# STM32C5A3xx register map
File version: 1.0
Registers are 32-bit, read-write, reset 0x0 unless marked. A register's access mark holds for its fields unless they carry their own. Offsets are from the block's base; [hi:lo] are bit positions; {n}, {i} and the like mark numbered series.

## ICACHE — Instruction cache (ICACHE)
Base 0x40030400
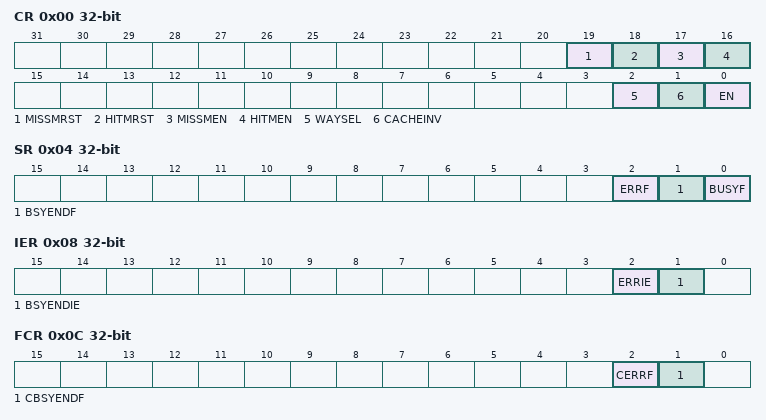
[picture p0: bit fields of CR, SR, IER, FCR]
0x00 CR — ICACHE control register
  [19] MISSMRST — miss monitor reset
  [18] HITMRST — hit monitor reset
  [17] MISSMEN — miss monitor enable
  [16] HITMEN — hit monitor enable
  [2] WAYSEL — cache associativity mode selection
  [1] CACHEINV — cache invalidation
  [0] EN — enable
0x04 SR ro — ICACHE status register
  [2] ERRF — cache error flag
  [1] BSYENDF — busy end flag
  [0] BUSYF — busy flag
0x08 IER — ICACHE interrupt enable register
  [2] ERRIE — interrupt enable on cache error
  [1] BSYENDIE — interrupt enable on busy end
0x0C FCR — ICACHE flag clear register
  [2] CERRF — clear cache error flag
  [1] CBSYENDF — clear busy end flag
0x10 HMONR ro — ICACHE hit monitor register
  [31:0] HITMON — cache hit monitor counter
0x14 MMONR ro — ICACHE miss monitor register
  [15:0] MISSMON — cache miss monitor counter
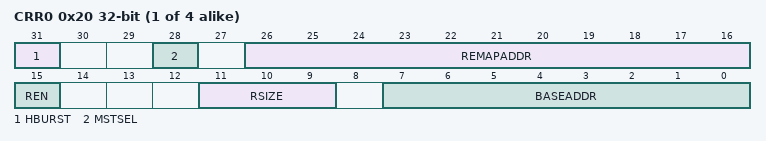
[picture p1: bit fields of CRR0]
{0x20+4i} CRR{i} (i=0..3) — ICACHE region {i} configuration register
  [31] HBURST — output burst type for region x
  [28] MSTSEL — AHB cache master selection for region x
  [26:16] REMAPADDR — remapped address for region x
  [15] REN — enable for region x
  [11:9] RSIZE — size for region x
  [7:0] BASEADDR — base address for region x

## GPIOA — General Purpose I/O (GPIO)
Base 0x42020000
Same registers: GPIOB 0x42020400, GPIOC 0x42020800, GPIOD 0x42020C00, GPIOE 0x42021000, GPIOF 0x42021400, GPIOG 0x42021800, GPIOH 0x42021C00
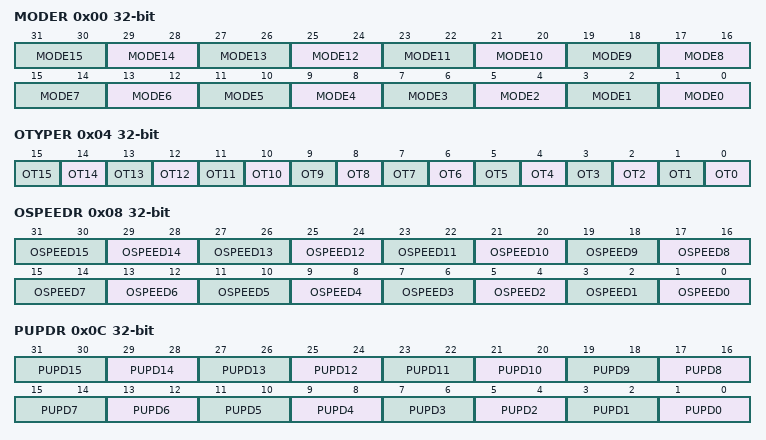
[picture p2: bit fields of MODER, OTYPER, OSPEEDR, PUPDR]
0x00 MODER — GPIO port mode register
  [2n+1:2n] MODE{n} (n=0..15) — Port x configuration I/O pin y
0x04 OTYPER — GPIO port output type register
  [n] OT{n} (n=0..15) — Port x configuration I/O pin y
0x08 OSPEEDR — GPIO port output speed register
  [2n+1:2n] OSPEED{n} (n=0..15) — Port x configuration I/O pin y
0x0C PUPDR — GPIO port pull-up/pull-down register
  [2n+1:2n] PUPD{n} (n=0..15) — Port x configuration I/O pin y
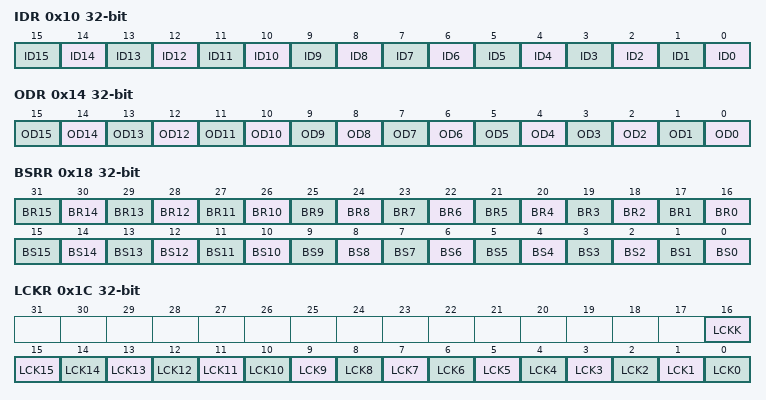
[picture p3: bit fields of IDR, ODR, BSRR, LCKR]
0x10 IDR ro — GPIO port input data register
  [n] ID{n} (n=0..15) — Port x input data I/O pin y
0x14 ODR — GPIO port output data register
  [n] OD{n} (n=0..15) — Port output data I/O pin y
0x18 BSRR — GPIO port bit set/reset register
  [n+16] BR{n} (n=0..15) — Port x reset I/O pin y
  [n] BS{n} (n=0..15) — Port x set I/O pin y
0x1C LCKR — GPIO port configuration lock register
  [16] LCKK — Lock key
  [n] LCK{n} (n=0..15) — Port x lock I/O pin y
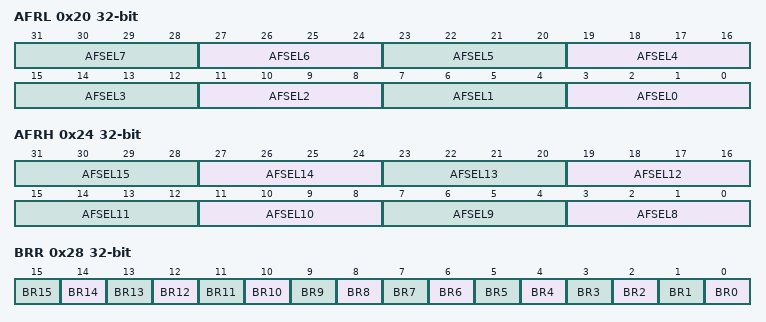
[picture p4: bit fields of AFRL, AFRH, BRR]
0x20 AFRL — GPIO alternate function register
  [4n+3:4n] AFSEL{n} (n=0..7)
0x24 AFRH — GPIO alternate function register
  [4n-29:4n-32] AFSEL{n} (n=8..15)
0x28 BRR — GPIO port bit reset register
  [n] BR{n} (n=0..15) — Port x reset IO pin y

## ADC12_COMMON
Base 0x42028300
0x00 CSR ro — ADC common status register
0x08 CCR — ADC common control register
0x0C CDR ro — ADC common regular data register for dual mode
0x10 CDR2 ro — ADC common regular data register for dual mode

## DAC1 — Digital to Analog Converter
Base 0x42028400
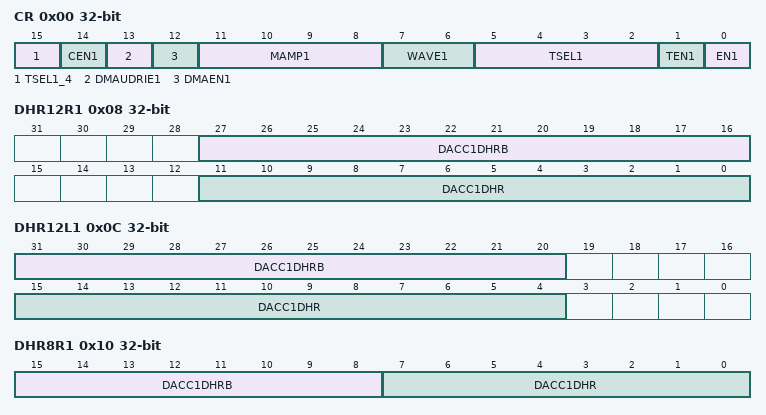
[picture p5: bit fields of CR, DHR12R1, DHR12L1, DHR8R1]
0x00 CR — DAC control register
  [15] TSEL1_4 — DAC channel1 trigger selection
  [14] CEN1 — DAC channel1 calibration enable
  [13] DMAUDRIE1
  [12] DMAEN1 — DAC channel1 DMA enable
  [11:8] MAMP1 — DAC channel1 mask/amplitude selector
  [7:6] WAVE1
  [5:2] TSEL1 — DAC channel1 trigger selection
  [1] TEN1 — DAC channel1 trigger enable
  [0] EN1 — DAC channel1 enable
0x04 SWTRGR — DAC software trigger register
  [0] SWTRIG1
0x08 DHR12R1 — DAC channel1 12-bit right-aligned data holding register
  [27:16] DACC1DHRB, [11:0] DACC1DHR
0x0C DHR12L1 — DAC channel1 12-bit left aligned data holding register
  [31:20] DACC1DHRB
  [15:4] DACC1DHR — DAC channel1 12-bit left-aligned data
0x10 DHR8R1 — DAC channel1 8-bit right aligned data holding register
  [15:8] DACC1DHRB — DAC channel1 8-bit right-aligned data
  [7:0] DACC1DHR — DAC channel1 8-bit right-aligned data
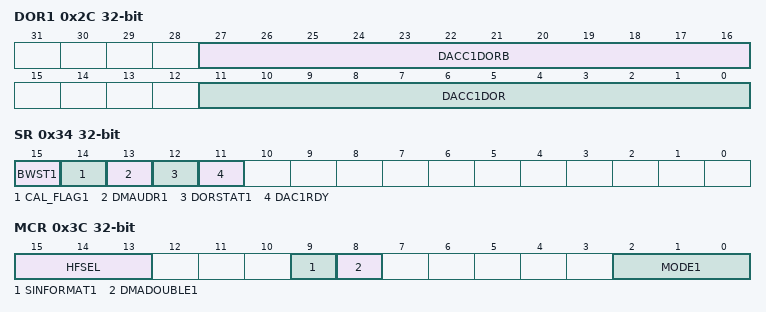
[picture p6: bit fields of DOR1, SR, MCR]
0x2C DOR1 ro — DAC channel1 data output register
  [27:16] DACC1DORB — DAC channel1 data output
  [11:0] DACC1DOR — DAC channel1 data output
0x34 SR — DAC status register
  [15] BWST1
  [14] CAL_FLAG1
  [13] DMAUDR1 — DAC channel1 DMA underrun flag
  [12] DORSTAT1
  [11] DAC1RDY — DAC channel1 ready status bit
0x38 CCR — DAC calibration control register
  [4:0] OTRIM1 — DAC channel1 offset trimming value
0x3C MCR — DAC mode control register
  [15:13] HFSEL
  [9] SINFORMAT1 — Enable signed format for DAC channel1
  [8] DMADOUBLE1 — DAC channel1 DMA double data mode
  [2:0] MODE1 — DAC channel1 mode
0x40 SHSR1 — DAC channel1 sample and hold sample time register
  [9:0] TSAMPLE1
0x48 SHHR — DAC sample and hold time register
  [9:0] THOLD1
0x4C SHRR — DAC sample and hold refresh time register
  [7:0] TREFRESH1
